# SMS_LITE_SEC_MGR_0_SMS_LITE_SEC_MGR_44234000h register map
Vendor: Texas Instruments
Peripheral module from a debugger description file (folder am62L).
Registers are 32-bit, read-write, reset 0x0 unless marked. A register's access mark holds for its fields unless they carry their own. Offsets are as the file gives them; lines under a group give offsets from that group; [hi:lo] are bit positions; {n}, {i} and the like mark numbered series; 'fields as' and 'values as' point back to an identical list; <NAME> marks a mode.

## SMS_LITE_SEC_MGR
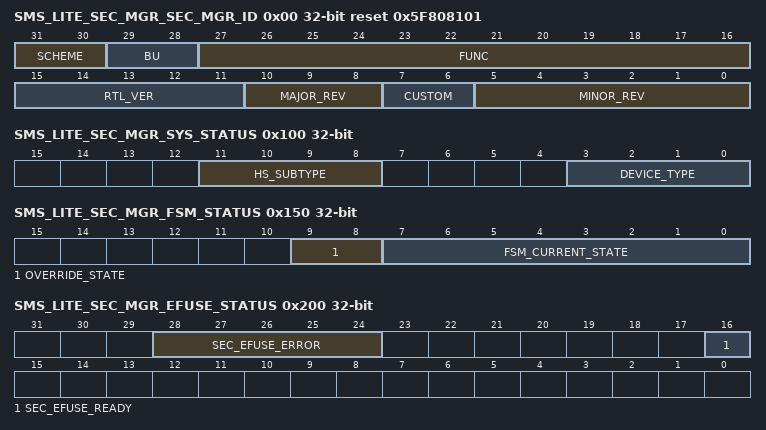
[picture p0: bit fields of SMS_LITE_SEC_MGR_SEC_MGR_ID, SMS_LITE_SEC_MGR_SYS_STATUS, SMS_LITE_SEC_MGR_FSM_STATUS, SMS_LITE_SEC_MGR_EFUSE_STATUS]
0x00 SMS_LITE_SEC_MGR_SEC_MGR_ID ro reset 0x5F808101 — This is the standard TI peripheral ID register that exists at address 0 in the peripheral space
  [31:30] SCHEME — Used to distinguish which ID numbering scheme is used. Reset Source: sms_custom_rst_mod_g_rst_n
  [29:28] BU — BU identifier Reset Source: sms_custom_rst_mod_g_rst_n
  [27:16] FUNC — Module family. Reset Source: sms_custom_rst_mod_g_rst_n
  [15:11] RTL_VER — RTL version. R of X.Y.R.Z Reset Source: sms_custom_rst_mod_g_rst_n
  [10:8] MAJOR_REV — Major revision. X of X.Y.R.Z Reset Source: sms_custom_rst_mod_g_rst_n
  [7:6] CUSTOM — Special version number Reset Source: sms_custom_rst_mod_g_rst_n
  [5:0] MINOR_REV — Minor revision. Y of X.Y.R.Z Reset Source: sms_custom_rst_mod_g_rst_n
0x100 SMS_LITE_SEC_MGR_SYS_STATUS ro — The System Status Register contains status information on the state of the security system. This is the only register that must be read to determine the status of the entire system. It is a readonly register and some bit will be replicated in other registers. This register is reset on POR only.
  [11:8] HS_SUBTYPE — This is the device subtype for HS and EMU devices. 10 Field SecurableElse Security Enforced
  [3:0] DEVICE_TYPE — Decoded device type 4'b00 GENERAL_PURPOSE114'b01 TEST014'b10 EMULATOR014'b10 HIGH_SECURITY10Other BAD
0x150 SMS_LITE_SEC_MGR_FSM_STATUS ro — The FSM Status Register contains Secure FSM state machine information
  [9:8] OVERRIDE_STATE — This is the override status 2'b00 No override2'b01 Override without DMSC2'b10 Reserved2'b11 Override with DMSC
  [7:0] FSM_CURRENT_STATE — This is the state machine FSM current state variable Reset Source: sms_custom_rst_mod_g_rst_n
0x200 SMS_LITE_SEC_MGR_EFUSE_STATUS ro — The EFUSE Status register contains status information on the state of the EFUSE scan chains. It is a read-only register with values from input ports.
  [28:24] SEC_EFUSE_ERROR — These bits reflect the value on the sec_efuse_error port Reset Source: sms_custom_rst_mod_g_rst_n
  [16] SEC_EFUSE_READY — These bits reflect the value on the sec_efuse_ready port Reset Source: sms_custom_rst_mod_g_rst_n
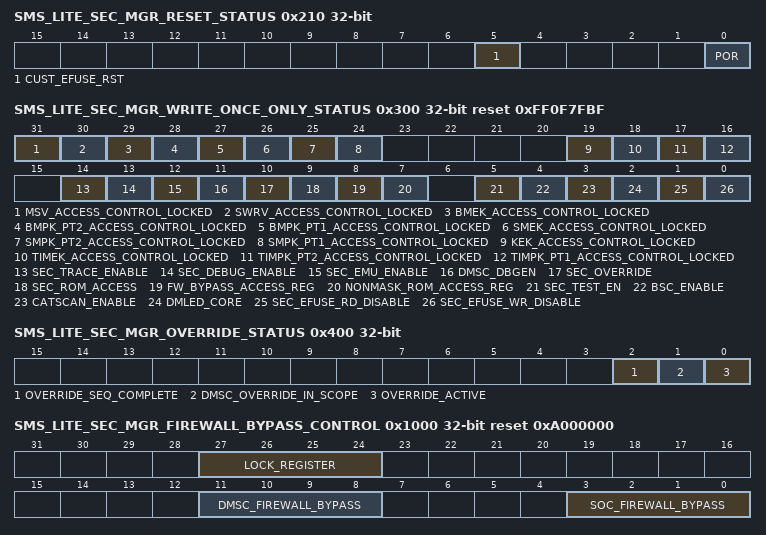
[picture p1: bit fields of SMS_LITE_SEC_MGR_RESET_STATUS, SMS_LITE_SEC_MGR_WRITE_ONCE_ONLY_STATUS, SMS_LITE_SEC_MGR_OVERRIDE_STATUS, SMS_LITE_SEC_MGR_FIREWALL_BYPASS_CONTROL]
0x210 SMS_LITE_SEC_MGR_RESET_STATUS ro — The Reset Status Register provides visibility of resets within the system. These bits are read-only and will be cleared when a 1 is written to a given bit location. They will record the fact that a given reset occurred.
  [5] CUST_EFUSE_RST — Captures reset events on port: sec_efc_fclrz Reset Source: sms_custom_rst_mod_g_rst_n
  [0] POR — Captures reset events on port: por_rst_n Reset Source: sms_custom_rst_mod_g_rst_n
0x300 SMS_LITE_SEC_MGR_WRITE_ONCE_ONLY_STATUS ro reset 0xFF0F7FBF — As a debug aid we need to be able to read the write-once only bits to know their state. This register makes all these write-once only flags visible in current state.
  [31] MSV_ACCESS_CONTROL_LOCKED — 0 MSV access control register locked1 MSV access control register not locked
  [30] SWRV_ACCESS_CONTROL_LOCKED — 0 SWRV access control register locked1 SWRV access control register not locked
  [29] BMEK_ACCESS_CONTROL_LOCKED — 0 BMEK access control register locked1 BMEK access control register not locked
  [28] BMPK_PT2_ACCESS_CONTROL_LOCKED — 0 BMPK-Part2 access control register locked1 BMPK-Part2 access control register not locked
  [27] BMPK_PT1_ACCESS_CONTROL_LOCKED — 0 BMPK-Part1 access control register locked1 BMPK-Part1 access control register not locked
  [26] SMEK_ACCESS_CONTROL_LOCKED — 0 SMEK access control register locked1 SMEK access control register not locked
  [25] SMPK_PT2_ACCESS_CONTROL_LOCKED — 0 SMPK-Part2 access control register locked1 SMPK-Part2 access control register not locked
  [24] SMPK_PT1_ACCESS_CONTROL_LOCKED — 0 SMPK-Part1 access control register locked1 SMPK-Part1 access control register not locked
  [19] KEK_ACCESS_CONTROL_LOCKED — 0 KEK access control register locked1 KEK access control register not locked
  [18] TIMEK_ACCESS_CONTROL_LOCKED — 0 TI MEK access control register locked1 TI MEK access control register not locked
  [17] TIMPK_PT2_ACCESS_CONTROL_LOCKED — 0 TI MPK-Part2 access control register locked1 TI MPK-Part2 access control register not locked
  [16] TIMPK_PT1_ACCESS_CONTROL_LOCKED — 0 TI MPK-Part1 access control register locked1 TI MPK-Part1 access control register not locked
  [14] SEC_TRACE_ENABLE — 0 Secure Trace Enable access control register locked1 Secure Trace Enable access control register not locked
  [13] SEC_DEBUG_ENABLE — 0 Secure Debug Enable access control register locked1 Secure Debug Enable access control register not locked
  [12] SEC_EMU_ENABLE — 0 Secure Emulation Enable access control register locked1 Secure Emulation Enable access control register not locked
  [11] DMSC_DBGEN — 0 DMSC Debug Enable access control register locked1 DMSC Debug Enable access control register not locked
  [10] SEC_OVERRIDE — 0 Security Override access control register locked1 Security Override access control register not locked
  [9] SEC_ROM_ACCESS — 0 Secure ROM access control register locked1 Secure ROM access control register not locked
  [8] FW_BYPASS_ACCESS_REG — 0 Firewall Bypass access control register locked1 Firewall Bypass access control register not locked
  [7] NONMASK_ROM_ACCESS_REG — 0 Non_masked ROM Access control register locked1 Non-Masked ROM Access control register not locked
  [5] SEC_TEST_EN — 0 Secure Test Enable access control register locked1 Secure Test Enable access control register not locked
  [4] BSC_ENABLE — 0 Boundary Scan Enable access control register locked1 Boundary Scan Enable access control register not locked
  [3] CATSCAN_ENABLE — 0 Catscan Enable access control register locked1 Catscan Enable access control register not locked
  [2] DMLED_CORE — 0 DMLED Core control register locked1 DMLED Core control register not locked
  [1] SEC_EFUSE_RD_DISABLE — 0 Security EFUSE Read Disable register locked1 Security EFUSE Read Disable register not locked
  [0] SEC_EFUSE_WR_DISABLE — 0 Security EFUSE Write Disable register locked1 Security EFUSE Write Disable register not locked
0x400 SMS_LITE_SEC_MGR_OVERRIDE_STATUS ro — This Register reflects the status of Override request.
  [2] OVERRIDE_SEQ_COMPLETE — 1 HW Override sequence finished
  [1] DMSC_OVERRIDE_IN_SCOPE — 0 DMSC Override not active1 DMSC Override active
  [0] OVERRIDE_ACTIVE — 0 Override not active0 Override active
0x500 SMS_LITE_SEC_MGR_EFUSE_JTAG_DISABLE_STATUS ro — This Register reflects the status of efuse based JTAG disable feature. Once JTAG has been disabled via Efuse, there can be no debug and TI cannot do any RMA.
  [3:0] JTAG_DISABLE — 4'b00 JTAG not permanently disabled via Efuse00Rest JTAG is disabled
0x700 SMS_LITE_SEC_MGR_TI_MPK_PART1_STATUS_REG_j ro — This register echoes the TI MPK-Part1 value, the MPK value can be muted via MPK Access control register.
  [31:0] TI_MPK — TI MP value as read from TI MPK Data Reg. This register is mere echo of Data Register Reset Source: sms_custom_rst_mod_g_rst_n
0x750 SMS_LITE_SEC_MGR_TI_MPK_PART2_STATUS_REG_j ro — This register echoes the TI MPK-Part2 value, the MPK value can be muted via MPK Access control register.
  fields as SMS_LITE_SEC_MGR_TI_MPK_PART1_STATUS_REG_j
0x780 SMS_LITE_SEC_MGR_TI_MEK_ID_STATUS_REG ro — This register echoes the TI MEK ID value, this is used to ID the key used for MEK.
  [31:0] TI_MEK_ID — TI MEK ID value as read from TI MEK ID data register, this is mere echo of TI MEK ID Register. Reset Source: sms_custom_rst_mod_g_rst_n
0x800 SMS_LITE_SEC_MGR_SMPK_PART1_STATUS_REG_j ro — This register echoes the SMPK-Part1 value, the MPK value can be muted via MPK Access control register.
  [31:0] SMPK — SMPK value as read from SMPK Data Register. This register is mere echo of SMPK Data register. Reset Source: sms_custom_rst_mod_g_rst_n
0x850 SMS_LITE_SEC_MGR_SMPK_PART2_STATUS_REG_j ro — This register echoes the SMPK-Part2 value, the MPK value can be muted via MPK Access control register.
  fields as SMS_LITE_SEC_MGR_SMPK_PART1_STATUS_REG_j
0x880 SMS_LITE_SEC_MGR_SMEK_ID_STATUS_REG ro — This register echoes the SMEK ID value, this is used to ID the key used for SMEK.
  [31:0] SMEK — SMEK ID value as read from SMEK ID data register, this is mere echo of SMEK ID Register. Reset Source: sms_custom_rst_mod_g_rst_n
0x900 SMS_LITE_SEC_MGR_BMPK_PART1_STATUS_REG_j ro — This register echoes the BMPK-Part1 value, the MPK value can be muted via MPK Access control register.
  [31:0] BMPK — BMPK value as read from BMPK Data Register. This register is mere echo of BMPK Data register. Reset Source: sms_custom_rst_mod_g_rst_n
0x950 SMS_LITE_SEC_MGR_BMPK_PART2_STATUS_REG_j ro — This register echoes the BMPK-Part2 value, the MPK value can be muted via MPK Access control register.
  fields as SMS_LITE_SEC_MGR_BMPK_PART1_STATUS_REG_j
0x980 SMS_LITE_SEC_MGR_BMEK_ID_STATUS_REG ro — This register echoes the BMEK ID value, this is used to ID the key used for BMEK.
  [31:0] BMEK — BMEK ID value as read from BMEK ID data register, this is mere echo of BMEK ID Register. Reset Source: sms_custom_rst_mod_g_rst_n
0xD00 SMS_LITE_SEC_MGR_SWRV_STATUS_REG_j ro — This register echoes the SWRV value, the SWRV value can be muted via SWRV Access control register.
  [31:0] SWRV — SWRV value as read from SWRV Data Register. This register is mere echo of SWRV Data register. Reset Source: sms_custom_rst_mod_g_rst_n
0xD50 SMS_LITE_SEC_MGR_MSV_STATUS_REG ro — This register echoes the MSV value, the MSV value can be muted via MSV Access control register.
  [23:0] MSV — MSV value as read from MSV Data Register. This register is mere echo of MSV Data register. Reset Source: sms_custom_rst_mod_g_rst_n
0x1000 SMS_LITE_SEC_MGR_FIREWALL_BYPASS_CONTROL reset 0xA000000 — This register controls the bypass feature for all SoC firewall. Once locked, the register cannot be changed till POR.
  [27:24] LOCK_REGISTER — Unlock code is 0xA, if value is anything else the register locks, once locked this register cannot be changed till POR. Rest Register is locked10 Register is unlocked
  [11:8] DMSC_FIREWALL_BYPASS — Writing code 0xA will put DMSC firewall in bypass mode. Please refer to firewall spec for bypass mode operation. 0 Not in bypass mode10 Bypass
  [3:0] SOC_FIREWALL_BYPASS — Writing code 0xA will put all SoC firewall in bypass mode, excluding DMSC. Please refer to firewall spec for bypass mode operation 0 Not in bypass mode10 Bypass
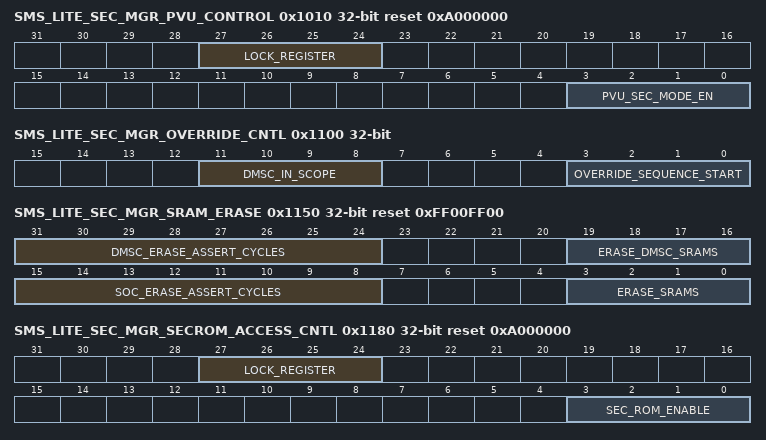
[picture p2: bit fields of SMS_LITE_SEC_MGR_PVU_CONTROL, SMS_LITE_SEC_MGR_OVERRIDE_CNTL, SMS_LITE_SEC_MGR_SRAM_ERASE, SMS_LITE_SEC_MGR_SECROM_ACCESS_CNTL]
0x1010 SMS_LITE_SEC_MGR_PVU_CONTROL reset 0xA000000 — This register controls the security of PVU/IO-MMU module. Once locked, the register cannot be changed till POR.
  [27:24] LOCK_REGISTER — Unlock code is 0xA, if value is anything else the register locks, once locked this register cannot be changed till POR. Reset Source: sms_custom_rst_mod_g_rst_n
  [3:0] PVU_SEC_MODE_EN — Writing code 0xA allows PVC to operate in secure mode. Reset Source: sms_custom_rst_mod_g_rst_n
0x1100 SMS_LITE_SEC_MGR_OVERRIDE_CNTL — Override sequence start register, writing 0xA start the override sequence as documented. This register can only be written once during each POR and the value is sticky.
  [11:8] DMSC_IN_SCOPE — Writing code 0xA will put DMSC also in in scope of override, please refer to flow in previous section. This must be set along with override_sequence_start. Reset Source: sms_custom_rst_mod_g_rst_n
  [3:0] OVERRIDE_SEQUENCE_START — Override sequence start bit, Writing 0xA starts the operation Reset Source: sms_custom_rst_mod_g_rst_n
0x1104 SMS_LITE_SEC_MGR_OVERRIDE_DELAY_LOOP reset 0xFFFF — This register holds delay loop counter to allow DMSC to enter WFI before DMSC override is effeictive.
  [31:0] DMSC_OVERRIDE_DELAY_LOOP_CNT — DMSC Delay loop counter, override is effective when counter reaches Zero. This counter is running on PLL output clock , hence ROM/SW must ensure delay based on system PLL DMSC clock. Reset Source: sms_custom_rst_mod_g_rst_n
0x1150 SMS_LITE_SEC_MGR_SRAM_ERASE reset 0xFF00FF00 — This register control the Erase function of SRAM and ROM access control.
  [31:24] DMSC_ERASE_ASSERT_CYCLES — This MMR control the assertion time of DMSC Erase signal. This is required as certain SRAM erase logic may have time requirement to keep signal asserted. Runs as same clock as Sec-mgr clock. Reset Source: sms_custom_rst_mod_g_rst_n
  [19:16] ERASE_DMSC_SRAMS — Writing code 0xA will send signal to erase DMSC SRAM, this will erase all DMSC SRAM including data and code SRAM. Care must be taken to ensure DMSC Cortex-M3 is in not executing from SRAM when this signal is asserted. Reset Source: sms_custom_rst_mod_g_rst_n
  [15:8] SOC_ERASE_ASSERT_CYCLES — This MMR control the assertion time of SOC Erase signal. This is required as certain SRAM erase logic may have time requirement to keep signal asserted. Runs as same clock as Sec-mgr clock. Reset Source: sms_custom_rst_mod_g_rst_n
  [3:0] ERASE_SRAMS — Writing code 0xA will send signal to all SoC level SRAM to erase the RAM. This bit does not erase DMSC internal SRAM. Reset Source: sms_custom_rst_mod_g_rst_n
0x1180 SMS_LITE_SEC_MGR_SECROM_ACCESS_CNTL reset 0xA000000 — This register controls the Erase function of SRAM and ROM access control.
  [27:24] LOCK_REGISTER — Unlock code is 0xA, if value is anything else the register locks, once locked this register cannot be changed till POR Reset Source: sms_custom_rst_mod_g_rst_n
  [3:0] SEC_ROM_ENABLE — Writing code 0xA will enable access to secure ROM, for all other value the secure ROM is disabled. Reset Source: sms_custom_rst_mod_g_rst_n
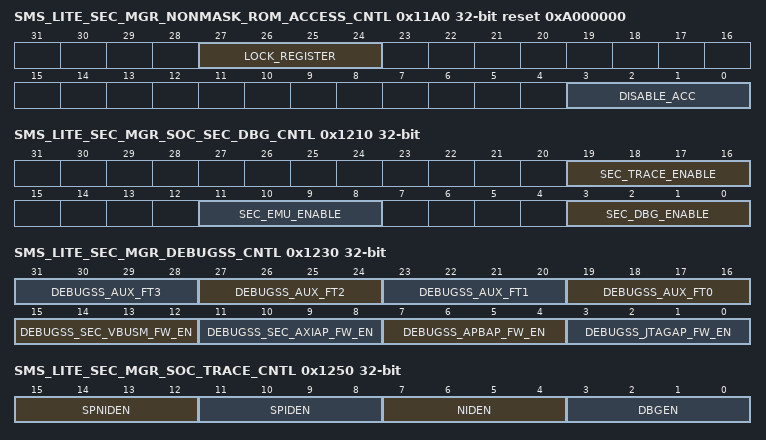
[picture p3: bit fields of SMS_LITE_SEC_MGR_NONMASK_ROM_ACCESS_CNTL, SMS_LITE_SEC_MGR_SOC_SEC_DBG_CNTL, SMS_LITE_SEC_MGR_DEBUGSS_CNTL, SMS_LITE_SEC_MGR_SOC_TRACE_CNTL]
0x11A0 SMS_LITE_SEC_MGR_NONMASK_ROM_ACCESS_CNTL reset 0xA000000 — This register controls the nonmask_rom_enable output of the security manager. This output should be connected to disable access to the non-mask part of the ROM.
  [27:24] LOCK_REGISTER — Unlock code is 0xA, if value is anything else the register locks, once locked this register cannot be changed till POR Reset Source: sms_custom_rst_mod_g_rst_n
  [3:0] DISABLE_ACC — Writing code 0xA will begin the countdown to drive the nonmask_rom_enable output to 0. Reset Source: sms_custom_rst_mod_g_rst_n
0x11A4 SMS_LITE_SEC_MGR_NONMASK_ROM_DISABLE_DELAY_CNTR reset 0x64 — This register contains the Non-Mask ROM Disable Delay counter. This register gets NO initial value from Efuses/Flash. This register defaults to reset state in case of a warm reset.
  [15:0] CNTR — When the Non-Mask ROM disable begins the countdown, this will count down to zero. Reset Source: sms_custom_rst_mod_g_rst_n
0x1200 SMS_LITE_SEC_MGR_DMSC_DEBUG_CNTL — This register controls the DMSC Debug TAP. This register can be locked. This is pure SW managed register with NO initial value from Efuses.
  [3:0] DMSC_DBGEN_ENABLE — Writing code 0xA will enable Debug for DMSC. SW/ROM must be very careful using this. This is set for EMU mode. Reset Source: sms_custom_rst_mod_g_rst_n
0x1210 SMS_LITE_SEC_MGR_SOC_SEC_DBG_CNTL — This register controls the SoC Debug TAPs. This register can be locked. This is pure SW managed register with NO initial value from Efuses.
  [19:16] SEC_TRACE_ENABLE — Writing code 0xA will allow Trace for SoC. This assert Trace signals that are also controlled by “SoC Debug/trace control” register. Once set all security emulation are active. SW/ROM must be very careful using this. Reset Source: sms_custom_rst_mod_g_rst_n
  [11:8] SEC_EMU_ENABLE — Writing code 0xA will allow Secure Emulation for All SoC. Once set all security emulation are active. SW/ROM must be very careful using this. Reset Source: sms_custom_rst_mod_g_rst_n
  [3:0] SEC_DBG_ENABLE — Writing code 0xA will enable full Debug for SoC. This open complete SoC Debug TAPs, except DMSC. Reset Source: sms_custom_rst_mod_g_rst_n
0x1220 SMS_LITE_SEC_MGR_DEBUGSS_DOM reset 0x3CE — This register controls the DebugSS DOM
  [10:0] DEBUGSS_SEC_CTL_DOM — DOM value as per DebugSS spec Reset Source: sms_custom_rst_mod_g_rst_n
0x1230 SMS_LITE_SEC_MGR_DEBUGSS_CNTL — This register controls DebugSS Internal Firewall. This register can be locked. Once locked, the register cannot be changed until POR
  [4n+19:4n+16] DEBUGSS_AUX_FT{n} (n=0..3) — Writing code 0xA will assert signal debugss_aux_ft_signals bit {n} Reset Source: sms_custom_rst_mod_g_rst_n
  [15:12] DEBUGSS_SEC_VBUSM_FW_EN — Writing code 0xA will enable DebugSS internal VBUSM firewall interface, else it is disabled Reset Source: sms_custom_rst_mod_g_rst_n
  [11:8] DEBUGSS_SEC_AXIAP_FW_EN — Writing code 0xA will enable DebugSS internal AXI AP firewall interface, else it is disabled Reset Source: sms_custom_rst_mod_g_rst_n
  [7:4] DEBUGSS_APBAP_FW_EN — Writing code 0xA will enable DebugSS internal APB AP firewall interface, else it is disabled Reset Source: sms_custom_rst_mod_g_rst_n
  [3:0] DEBUGSS_JTAGAP_FW_EN — Writing code 0xA will enable DebugSS internal JTAG firewall interface, else it is disabled Reset Source: sms_custom_rst_mod_g_rst_n
0x1234 SMS_LITE_SEC_MGR_DEBUGSS_DBG_TAP_FW_EN — This register controls the DebugSS Debug Tap. This register can be locked. Once locked, the register cannot be changed till POR. This register gets NO initial value from Efuses
  [31:0] DEBUGSS_DBG_TAP_FW_EN — DebugSS Debug Tap Firewall Enable Reset Source: sms_custom_rst_mod_g_rst_n
0x1238 SMS_LITE_SEC_MGR_DEBUGSS_TEST_TAP_FW_EN — This register controls the DebugSS Test Tap. This register can be locked. Once locked, the register cannot be changed till POR. This register gets NO initial value from Efuses
  [31:0] DEBUGSS_TEST_TAP_FW_EN — DebugSS Test Tap Firewall Enable Reset Source: sms_custom_rst_mod_g_rst_n
0x123C SMS_LITE_SEC_MGR_DEBUGSS_PWR_FW_EN — This register controls the DebugSS Firewall Enable. This register can be locked. Once locked, the register cannot be changed till POR. This register gets NO initial value from Efuses
  [31:0] DEBUGSS_PWR_FW_EN — DebugSS Security Firewall Enable Reset Source: sms_custom_rst_mod_g_rst_n
0x1240 SMS_LITE_SEC_MGR_DEBUGSS_CMX_FW_EN — This register controls the DebugSS Core Enable. This register can be locked. Once locked, the register cannot be changed till POR. This register gets NO initial value from Efuses
  [31:0] DEBUGSS_CMX_FW_EN — DebugSS Core Enable Reset Source: sms_custom_rst_mod_g_rst_n
0x1244 SMS_LITE_SEC_MGR_DEBUGSS_AUX — This register controls the Debugss aux signals. This register can be locked. Once locked, the register cannot be changed till POR. This register gets NO initial value from Efuses.
  [31:0] DEBUGSS_AUX — DebugSS aux reserved signals Reset Source: sms_custom_rst_mod_g_rst_n
0x1250 SMS_LITE_SEC_MGR_SOC_TRACE_CNTL — This register controls SoC Trace. This register can be locked. Once locked, the register cannot be changed till POR. This register gets NO initial value from Efuses.
  [15:12] SPNIDEN — Writing 0xA will enable spniden Reset Source: sms_custom_rst_mod_g_rst_n
  [11:8] SPIDEN — Writing 0xA will enable spiden Reset Source: sms_custom_rst_mod_g_rst_n
  [7:4] NIDEN — Writing 0xA will enable niden Reset Source: sms_custom_rst_mod_g_rst_n
  [3:0] DBGEN — Writing 0xA will enable dbgen Reset Source: sms_custom_rst_mod_g_rst_n
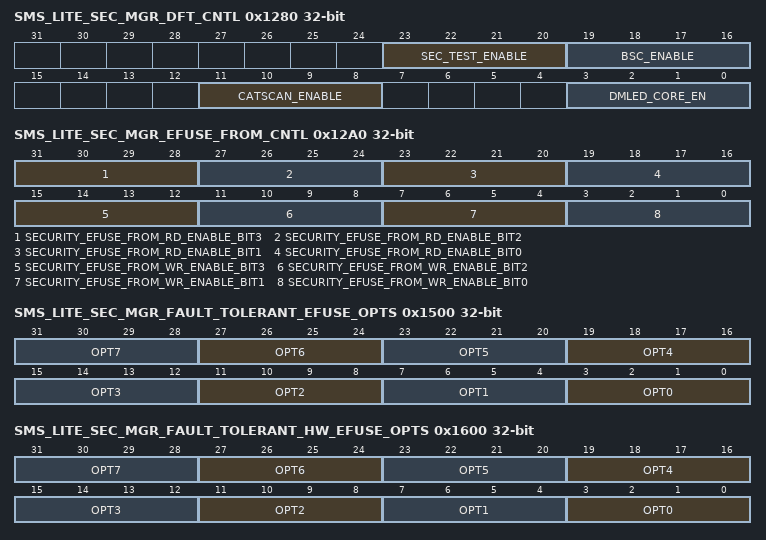
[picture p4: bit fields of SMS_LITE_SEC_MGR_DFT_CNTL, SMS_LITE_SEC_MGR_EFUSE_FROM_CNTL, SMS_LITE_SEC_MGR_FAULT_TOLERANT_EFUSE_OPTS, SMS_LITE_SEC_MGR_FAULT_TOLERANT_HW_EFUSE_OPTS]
0x1280 SMS_LITE_SEC_MGR_DFT_CNTL — This register controls the DFT access of the device. These bits can only be written once during each POR.
  [23:20] SEC_TEST_ENABLE — Control the use of Test Enable. Writing a 0xA will enable test Reset Source: sms_custom_rst_mod_g_rst_n
  [19:16] BSC_ENABLE — Control the use of Boundary Scan Chain. Writing a 0xA will enable BSCAN Reset Source: sms_custom_rst_mod_g_rst_n
  [11:8] CATSCAN_ENABLE — Control the use of the CatScan module. Writing a 0xA will enable CATSCAN Reset Source: sms_custom_rst_mod_g_rst_n
  [3:0] DMLED_CORE_EN — Writing code 0xA will allow DMLED module to operate. Else DMLED mode is disabled. Reset Source: sms_custom_rst_mod_g_rst_n
0x12A0 SMS_LITE_SEC_MGR_EFUSE_FROM_CNTL — This register controls the Efuse access of the device. These bits can only be written once during each POR. This is pure SW managed register with NO initial value from Efuses.
  [31:28] SECURITY_EFUSE_FROM_RD_ENABLE_BIT3 — Reserved Reset Source: sms_custom_rst_mod_g_rst_n
  [27:24] SECURITY_EFUSE_FROM_RD_ENABLE_BIT2 — Customer General OTP Programmable FROM EFUSE Read Disable. 0xA - Reads allowed to Customer General OTP EFUSE FROM. Else - Reads not allowed to Customer General OTP EFUSE FROM. Reset Source: sms_custom_rst_mod_g_rst_n
  [23:20] SECURITY_EFUSE_FROM_RD_ENABLE_BIT1 — Customer Key Material Programmable FROM EFUSE Read Disable. 0xA - Reads allowed to Customer Key Material EFUSE FROM. Else - Reads not allowed to Customer Key Material EFUSE FROM. Reset Source: sms_custom_rst_mod_g_rst_n
  [19:16] SECURITY_EFUSE_FROM_RD_ENABLE_BIT0 — TI Key Material Programmable FROM EFUSE Read Disable. 0xA - Reads allowed to TI Key Material EFUSE FROM. Else - Reads not allowed to TI Key Material EFUSE FROM. Reset Source: sms_custom_rst_mod_g_rst_n
  [15:12] SECURITY_EFUSE_FROM_WR_ENABLE_BIT3 — Reserved Reset Source: sms_custom_rst_mod_g_rst_n
  [11:8] SECURITY_EFUSE_FROM_WR_ENABLE_BIT2 — Customer General OTP Programmable FROM EFUSE Write Disable. 0xA - Writes allowed to Customer General OTP EFUSE FROM. Else - Writes not allowed to Customer General OTP EFUSE FROM. Reset Source: sms_custom_rst_mod_g_rst_n
  [7:4] SECURITY_EFUSE_FROM_WR_ENABLE_BIT1 — Customer Key Material Programmable FROM EFUSE Write Disable. 0xA - Writes allowed to Customer Key Material EFUSE FROM. Else - Writes not allowed to Customer Key Material EFUSE FROM. Reset Source: sms_custom_rst_mod_g_rst_n
  [3:0] SECURITY_EFUSE_FROM_WR_ENABLE_BIT0 — TI Key Material Programmable FROM EFUSE Write Disable. 0xA - Writes allowed to TI Key Material EFUSE FROM. Else - Writes not allowed to TI Key Material EFUSE FROM. Reset Source: sms_custom_rst_mod_g_rst_n
0x1500 SMS_LITE_SEC_MGR_FAULT_TOLERANT_EFUSE_OPTS — This register holds the fault tolerant options that are sensitive from security standpoint. ROM defines these options, ROM can choose to use this option as single bit flag, however for security options fault tolerant field must be used. This register gets initial value from Security Efuse FROM.
  [4n+3:4n] OPT{n} (n=0..7) — If the value is 0xA, then selected option is enabled. Else: Selected option is disabled. ROM code defines this option bit Reset Source: sms_custom_rst_mod_g_rst_n
0x1510 SMS_LITE_SEC_MGR_NON_FAULT_TOLERANT_EFUSE_OPTS — This register holds device config, these are non-fault tolerant. This register gets initial value from Security Efuse FROM.
  [31:0] OPTS — This register holds device config data. ROM code defines these fields Reset Source: sms_custom_rst_mod_g_rst_n
0x1600 SMS_LITE_SEC_MGR_FAULT_TOLERANT_HW_EFUSE_OPTS ro — This register control external signals that can be used to control various/misc security knobs at SoC, it is not defined by security Manager. This register gets initial value from Security Efuse FROM.
  [4n+3:4n] OPT{n} (n=0..7) — If the value is 0xA, then bit[{n}] of ft_hw_efuse_security_ctrl is set (asserted), else it remain clear (de-asserted). ROM/SW cannot change this config, this is true HW config Reset Source: sms_custom_rst_mod_g_rst_n
0x1610 SMS_LITE_SEC_MGR_NON_FAULT_TOLERANT_HW_EFUSE_OPTS ro — This register holds device config, these are non-fault tolerant. This register gets initial value from SecurityEfuse FROM.
  [31:0] OPTS — This register holds device config data. HW uses this to enable/disable security feature. This drives output signal nonft_hw_efuse_security_ctrl[31:0]. ROM/SW cannot change this config, this is true HW config Reset Source: sms_custom_rst_mod_g_rst_n
0x1650 SMS_LITE_SEC_MGR_EXT_SEC_CNTL_SIG — This register holds device config, these are non-fault tolerant. This is pure SW managed register with NO initial value from Efuses.
  [31:0] CNTL — This register holds device config data. SW/ROM can write this value that drives the external pins on IP. This drives nonft_hw_regs_security_ctrl[31:0] Reset Source: sms_custom_rst_mod_g_rst_n
0x1660 SMS_LITE_SEC_MGR_EXT_SEC_DATA_CNTL_j — These set of 4 registers hold the value to be driven on ext_security_data_signal[127:0], security manager takes no action on this data signals. This is pure SW managed register with NO initial value from Efuses.
  [31:0] DATA — These set of 4 registers drive the output signal nonft_hw_regs_security_data[127:0], security manager do not take any action based on value of this signal, it is purely for SoC level security data. Reset Source: sms_custom_rst_mod_g_rst_n
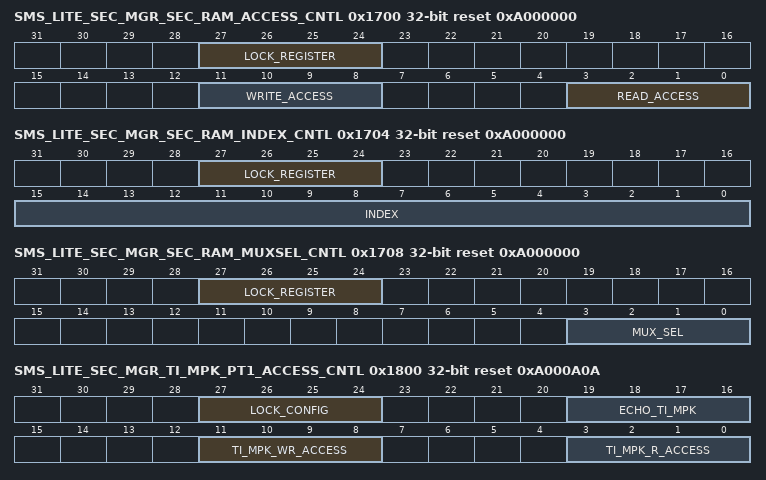
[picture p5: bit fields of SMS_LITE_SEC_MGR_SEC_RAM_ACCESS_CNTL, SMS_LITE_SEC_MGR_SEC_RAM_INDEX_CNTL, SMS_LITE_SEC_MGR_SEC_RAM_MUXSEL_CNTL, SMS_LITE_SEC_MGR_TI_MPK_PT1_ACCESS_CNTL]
0x1700 SMS_LITE_SEC_MGR_SEC_RAM_ACCESS_CNTL reset 0xA000000 — This register controls access to the secure RAM, driving the secure_ram_read_access and secure_ram_write_access pins. Once locked, the register cannot be changed until warm reset or POR. This register gets NO initial value from Efuses. These registers defaults to reset state in case of a warm reset, including unlocking of Lock.
  [27:24] LOCK_REGISTER — Unlock code is 0xA, if value is anything else the register locks, once locked this register cannot be changed until POR or warm reset Reset Source: sms_custom_rst_mod_g_rst_n
  [11:8] WRITE_ACCESS — Writing code 0xA will make the secure RAM writeable Reset Source: sms_custom_rst_mod_g_rst_n
  [3:0] READ_ACCESS — Writing code 0xA will make the secure RAM readable Reset Source: sms_custom_rst_mod_g_rst_n
0x1704 SMS_LITE_SEC_MGR_SEC_RAM_INDEX_CNTL reset 0xA000000 — This register controls the index for the secure RAM, driving the secure_ram_index pins. Once locked, the register cannot be changed until warm reset or POR. This register gets NO initial value from Efuses. This register defaults to reset state in case of a warm reset, including unlocking of Lock.
  [27:24] LOCK_REGISTER — Unlock code is 0xA, if value is anything else the register locks, once locked this register cannot be changed until POR or warm reset Reset Source: sms_custom_rst_mod_g_rst_n
  [15:0] INDEX — This drives the sec_ram_index output to the external secure RAM Reset Source: sms_custom_rst_mod_g_rst_n
0x1708 SMS_LITE_SEC_MGR_SEC_RAM_MUXSEL_CNTL reset 0xA000000 — This register controls the mux selection for the secure RAM, driving the secure_ram_mux_sel pin. Once locked, the register cannot be changed until warm reset or POR. This register gets NO initial value from Efuses. This register defaults to reset state in case of a warm reset, including unlocking of Lock.
  [27:24] LOCK_REGISTER — Unlock code is 0xA, if value is anything else the register locks, once locked this register cannot be changed until POR or warm reset Reset Source: sms_custom_rst_mod_g_rst_n
  [3:0] MUX_SEL — Writing code 0xA will make the sec_ram_mux_sel output go high Reset Source: sms_custom_rst_mod_g_rst_n
0x1800 SMS_LITE_SEC_MGR_TI_MPK_PT1_ACCESS_CNTL reset 0xA000A0A — This Register controls the access/permission of all TI MPK-Part1 Data Registers. If both Read and Write access are not selected, than all TI MPK-Part1 Data registers become invisible both in control and status section. This is pure SW managed register with NO initial value from Efuses.
  [27:24] LOCK_CONFIG — Unlock code is 0xA. If value is anything else the register locks. Once locked this register cannot be changed til POR. Reset Source: sms_custom_rst_mod_g_rst_n
  [19:16] ECHO_TI_MPK — Writing code 0xA will echo TI MPK value in TI MPK read only Status registers. Reset Source: sms_custom_rst_mod_g_rst_n
  [11:8] TI_MPK_WR_ACCESS — 0xA Write Access allowed. Else: No write access Reset Source: sms_custom_rst_mod_g_rst_n
  [3:0] TI_MPK_R_ACCESS — 0xA Read Access allowed. Else: No Read access. Reset Source: sms_custom_rst_mod_g_rst_n
0x1810 SMS_LITE_SEC_MGR_TI_MPK_PT1_DATA_REG_j — This register hold the TI MPK-Part1 value, the TI MPK-Part1 access/permission is controlled TI MPK-Part1 Access control register.
  [31:0] TI_MPK — TI MPK-Part1 value as read from Efuses. Reset Source: sms_custom_rst_mod_g_rst_n
0x1850 SMS_LITE_SEC_MGR_TI_MPK_PT1_BCH — This register holds BCH value for TI MPK-Part1. This register gets initial value from Security Efuse FROM
  [31:0] BCH — TI MPK-Part1 BCH Register. Initial value is loaded by HW, ROM reads Raw TI MPK-Part1 data and BCH register to carry out error correction. If the BCH register is Zero, then ROM must ignore BCH check and treat the raw data as golden. Reset Source: sms_custom_rst_mod_g_rst_n
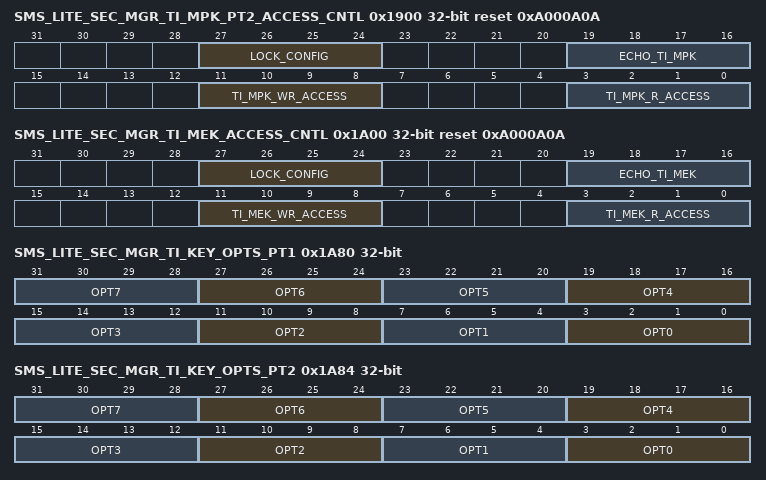
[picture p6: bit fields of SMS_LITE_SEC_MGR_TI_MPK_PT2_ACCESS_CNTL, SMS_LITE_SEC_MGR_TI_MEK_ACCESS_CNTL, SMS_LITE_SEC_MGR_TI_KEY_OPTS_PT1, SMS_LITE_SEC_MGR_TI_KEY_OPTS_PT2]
0x1900 SMS_LITE_SEC_MGR_TI_MPK_PT2_ACCESS_CNTL reset 0xA000A0A — This Register controls the access/permission of all TI MPK-Part2 Data Registers. If both Read and Write access are not selected, than all TI MPK-Part2 Data registers become invisible both in control and status section. This is pure SW managed register with NO initial value from Efuses.
  fields as SMS_LITE_SEC_MGR_TI_MPK_PT1_ACCESS_CNTL
0x1910 SMS_LITE_SEC_MGR_TI_MPK_PT2_DATA_REG_j — This register hold the TI MPK-Part2 value, the TI MPK-Part2 access/permission is controlled TI MPK-Part2 Access control register.
  [31:0] TI_MPK — TI MPK-Part2 value as read from Efuses. Reset Source: sms_custom_rst_mod_g_rst_n
0x1950 SMS_LITE_SEC_MGR_TI_MPK_PT2_BCH — This register holds BCH value for TI MPK-Part2. This register gets initial value from Security Efuse FROM
  [31:0] BCH — TI MPK-Part2 BCH Register. Initial value is loaded by HW, ROM reads Raw TI MPK-Part2 data and BCH register to carry out error correction. If the BCH register is Zero, then ROM must ignore BCH check and treat the raw data as golden. Reset Source: sms_custom_rst_mod_g_rst_n
0x1A00 SMS_LITE_SEC_MGR_TI_MEK_ACCESS_CNTL reset 0xA000A0A — This Register controls the access/permission of all TI MEK Data Registers. If both Read and Write access are not selected, than all TI MEK Data registers become invisible.
  [27:24] LOCK_CONFIG — Unlock code is 0xA. If value is anything else the register locks, once locked this register cannot be changed til POR Reset Source: sms_custom_rst_mod_g_rst_n
  [19:16] ECHO_TI_MEK — Writing code 0xA will echo TI MEK ID value in status register, this can used by public code to check the key used for Encryption. This must NOT be function of actual TI MEK value, rather a mere index. Reset Source: sms_custom_rst_mod_g_rst_n
  [11:8] TI_MEK_WR_ACCESS — 0xA Write Access allowed. Else: No write access Reset Source: sms_custom_rst_mod_g_rst_n
  [3:0] TI_MEK_R_ACCESS — 0xA Read Access allowed. Else: No Read access. Reset Source: sms_custom_rst_mod_g_rst_n
0x1A04 SMS_LITE_SEC_MGR_TI_MEK_ID — TI MEK ID Data Register
  [31:0] TI_MEK_ID — TI MEK ID, used by public code to check the key used for Encryption. This must NOT be function of actual TI MEK value, rather a mere index. SW has full flexibility to use these 32-bits as desired to ID the TI MEK key. Reset Source: sms_custom_rst_mod_g_rst_n
0x1A10 SMS_LITE_SEC_MGR_TI_MEK_DATA_REG_j — This register hold the TI MEK value, the TI MEK access/permission is controlled MEK Access control register.
  [31:0] TI_MEK — TI MEK value as read from Efuses. Reset Source: sms_custom_rst_mod_g_rst_n
0x1A50 SMS_LITE_SEC_MGR_TI_MEK_BCH — This register holds BCH value for TI MEK. This register gets initial value from Security Efuse FROM
  [31:0] BCH — TI MEK BCH Register. Initial value is loaded by HW, ROM reads Raw TI MEK data and BCH register to carry out error correction. If the BCH register is Zero, then ROM must ignore BCH check and treat the data as golden. Reset Source: sms_custom_rst_mod_g_rst_n
0x1A80 SMS_LITE_SEC_MGR_TI_KEY_OPTS_PT1 — This field is TI defined Keys options
  [4n+3:4n] OPT{n} (n=0..7) — If the value is 0xA, option is active. Else option is de-activated Reset Source: sms_custom_rst_mod_g_rst_n
0x1A84 SMS_LITE_SEC_MGR_TI_KEY_OPTS_PT2 — This field is TI defined Keys options
  fields as SMS_LITE_SEC_MGR_TI_KEY_OPTS_PT1
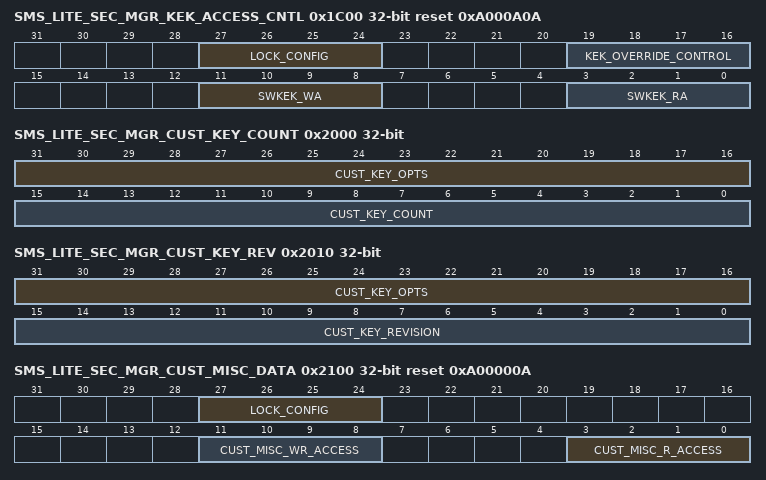
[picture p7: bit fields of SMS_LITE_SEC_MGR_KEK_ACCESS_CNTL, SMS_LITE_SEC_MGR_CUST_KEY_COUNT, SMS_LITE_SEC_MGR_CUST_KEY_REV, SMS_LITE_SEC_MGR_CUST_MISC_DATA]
0x1C00 SMS_LITE_SEC_MGR_KEK_ACCESS_CNTL reset 0xA000A0A — This Register controls the access/permission of all KEK Data Registers. If both Read and Write access are not selected, than all KEK Data registers become invisible.
  [27:24] LOCK_CONFIG — Unlock code is 0xA, if value is anything else the register locks, once locked this register cannot be changed til POR Reset Source: sms_custom_rst_mod_g_rst_n
  [19:16] KEK_OVERRIDE_CONTROL — 0xA Override KEK output to value from KEK override registers. Else KEK is as coming from KEK Efuses Reset Source: sms_custom_rst_mod_g_rst_n
  [11:8] SWKEK_WA — 0xA Write Access allowed to SW KEK register. Else No write access Reset Source: sms_custom_rst_mod_g_rst_n
  [3:0] SWKEK_RA — 0xA Write Access allowed to SW KEK register. Else No write access Reset Source: sms_custom_rst_mod_g_rst_n
0x1C10 SMS_LITE_SEC_MGR_SW_KEK_DATA_REG_j — These 8 registers register hold the KEK override value. This is pure SW managed register with NO initial value from Efuses
  [31:0] SW_KEK — SW defined KEK override value. Reset Source: sms_custom_rst_mod_g_rst_n
0x2000 SMS_LITE_SEC_MGR_CUST_KEY_COUNT ro — This register hold the number Keys that has been provisioned, this register must be written upfront during customer initial keys provisioning. This register must not be written in field else there can be security breach. This register gets initial value from Security Efuse FROM
  [31:16] CUST_KEY_OPTS — Customer defined efuse bits. Reset Source: sms_custom_rst_mod_g_rst_n
  [15:0] CUST_KEY_COUNT — 16-bit for field, double redundancy, that is used to keep count of keys provisioned in device. 0 - No customer keys present the system will boot from TI keys. Customer key Count must be non-zero for HS/EMU device to transaction from HS-FS/EMU-FS (Field Securable) to HS-SE/EMU-SE (Security Enforced) Reset Source: sms_custom_rst_mod_g_rst_n
0x2010 SMS_LITE_SEC_MGR_CUST_KEY_REV ro — This register holds what key (TI Key, SMPK and BMPK) is active at this point. This register gets initial value from Security Efuse FROM.
  [31:16] CUST_KEY_OPTS — Customer defined efuse bits. Reset Source: sms_custom_rst_mod_g_rst_n
  [15:0] CUST_KEY_REVISION — 16-bit for field , double redundancy. 0 - Use TI keys as root-of-trust. Else use Customer keys (SMPK/BMPK). Customer key Revision must be non-zero for HS/EMU device to transaction from HS-FS/EMU-FS (Field Securable) to HS-SE/EMU-SE (Security Enforced) Reset Source: sms_custom_rst_mod_g_rst_n
0x2100 SMS_LITE_SEC_MGR_CUST_MISC_DATA reset 0xA00000A — This Register controls the access/permission of all Customer Misc Data Registers. If both Read and Write access are not selected, than all CUST MISC Data registers become invisible.
  [27:24] LOCK_CONFIG — Unlock code is 0xA, if value is anything else the register locks, once locked this register cannot be changed till POR. Reset Source: sms_custom_rst_mod_g_rst_n
  [11:8] CUST_MISC_WR_ACCESS — 0xA Write Access allowed. Else: No write access Reset Source: sms_custom_rst_mod_g_rst_n
  [3:0] CUST_MISC_R_ACCESS — 0xA Read Access allowed. Else: No Read access. Reset Source: sms_custom_rst_mod_g_rst_n
0x2110 SMS_LITE_SEC_MGR_CUST_MISC_DATA_REG_j — This register hold the CUST MISC value, the CUST MISC access/permission is controlled CUST MISC Access control register. This can be used by customer to store critical security flags/data.
  [31:0] CUST_MISC — CUST MISC value. ROM/HW does no action based on value of this register. Reset Source: sms_custom_rst_mod_g_rst_n
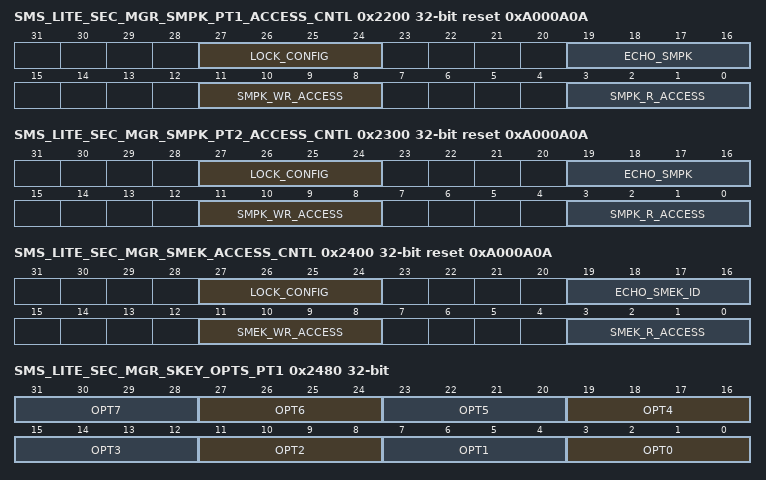
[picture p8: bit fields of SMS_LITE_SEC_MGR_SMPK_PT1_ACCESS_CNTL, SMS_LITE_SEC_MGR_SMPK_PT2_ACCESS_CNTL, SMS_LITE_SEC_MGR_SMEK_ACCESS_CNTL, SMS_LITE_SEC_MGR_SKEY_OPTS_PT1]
0x2200 SMS_LITE_SEC_MGR_SMPK_PT1_ACCESS_CNTL reset 0xA000A0A — This Register controls the access/permission of all SMPK-Part1 Data Registers. If both Read and Write access are not selected, than all SMPK Data registers become invisible.
  [27:24] LOCK_CONFIG — Unlock code is 0xA, if value is anything else the register locks, once locked this register cannot be changed till POR. Reset Source: sms_custom_rst_mod_g_rst_n
  [19:16] ECHO_SMPK — Writing code 0xA will echo SMPK value in SMPK read only Status registers. Reset Source: sms_custom_rst_mod_g_rst_n
  [11:8] SMPK_WR_ACCESS — 0xA Write Access allowed. Else: No write access Reset Source: sms_custom_rst_mod_g_rst_n
  [3:0] SMPK_R_ACCESS — 0xA Read Access allowed. Else: No Read access. Reset Source: sms_custom_rst_mod_g_rst_n
0x2210 SMS_LITE_SEC_MGR_SMPK_PT1_DATA_REG_j — This register hold the SMPK-Part1 value, the SMPK-Part1 access/permission is controlled SMPK-Part1 Access control register.
  [31:0] SMPK — SMPK-Part1 value as read from Efuses Reset Source: sms_custom_rst_mod_g_rst_n
0x2250 SMS_LITE_SEC_MGR_SMPK_PT1_BCH — This register holds BCH value for SMPK-Part1. This register gets initial value from Security Efuse FROM
  [31:0] BCH — SMPK-Part1 BCH Register. Initial value is loaded by HW, ROM reads Raw SMPK-Part1 data and BCH register to carry out error correction. If the BCH register is Zero, then ROM must ignore BCH check and treat the data as golden Reset Source: sms_custom_rst_mod_g_rst_n
0x2300 SMS_LITE_SEC_MGR_SMPK_PT2_ACCESS_CNTL reset 0xA000A0A — This Register controls the access/permission of all SMPK-Part2 Data Registers. If both Read and Write access are not selected, than all SMPK-Part2 Data registers become invisible in both control and status sections.
  fields as SMS_LITE_SEC_MGR_SMPK_PT1_ACCESS_CNTL
0x2310 SMS_LITE_SEC_MGR_SMPK_PT2_DATA_REG_j — This register hold the SMPK-Part2 value, the SMPK-Part2 access/permission is controlled SMPK-Part2 Access control register.
  [31:0] SMPK — SMPK-Part2 value as read from Efuses Reset Source: sms_custom_rst_mod_g_rst_n
0x2350 SMS_LITE_SEC_MGR_SMPK_PT2_BCH — This register holds BCH value for SMPK-Part2. This register gets initial value from Security Efuse FROM
  [31:0] BCH — SMPK-Part2 BCH Register. Initial value is loaded by HW, ROM reads Raw SMPK-Part2 data and BCH register to carry out error correction. If the BCH register is Zero, then ROM must ignore BCH check and treat the data as golden Reset Source: sms_custom_rst_mod_g_rst_n
0x2400 SMS_LITE_SEC_MGR_SMEK_ACCESS_CNTL reset 0xA000A0A — This Register controls the access/permission of all SMEK Data Registers. If both Read and Write access are not selected, than all SMEK Data registers become invisible.
  [27:24] LOCK_CONFIG — Writing code 0xA lock the config, once locked TI MPK access as set in this register cannot be changed till POR. Reset Source: sms_custom_rst_mod_g_rst_n
  [19:16] ECHO_SMEK_ID — Writing code 0xA will echo SMEK ID value in status register, this can used by public code to check the key used for Encryption. This must NOT be function of actual SMEK value, rather a mere index. Reset Source: sms_custom_rst_mod_g_rst_n
  [11:8] SMEK_WR_ACCESS — 0xA Write Access allowed. Else: No write access Reset Source: sms_custom_rst_mod_g_rst_n
  [3:0] SMEK_R_ACCESS — 0xA Read Access allowed. Else: No Read access. Reset Source: sms_custom_rst_mod_g_rst_n
0x2404 SMS_LITE_SEC_MGR_SMEK_ID — SMEK ID Data Register
  [31:0] SMEK_ID — SMEK ID, used by public code to check the key used for Encryption. This must NOT be function of actual SMEK value, rather a mere index. SW has full flexibility to use these 32-bits as desired to ID the SMEK key. Reset Source: sms_custom_rst_mod_g_rst_n
0x2410 SMS_LITE_SEC_MGR_SMEK_DATA_REG_j — This register hold the SMEK value, the SMEK access/permission is controlled MEK Access control register.
  [31:0] SMEK — SMEK value as read from Efuses Reset Source: sms_custom_rst_mod_g_rst_n
0x2450 SMS_LITE_SEC_MGR_SMEK_BCH — This register holds BCH value for SMEK-BCH. This register gets initial value from Security Efuse FROM
  [31:0] BCH — SMEK BCH Register. Initial value is loaded by HW, ROM reads Raw SMEK data and BCH register to carry out error correction. If the BCH register is Zero, then ROM must ignore BCH check and treat the data as golden Reset Source: sms_custom_rst_mod_g_rst_n
0x2480 SMS_LITE_SEC_MGR_SKEY_OPTS_PT1 — This field is Customer defined Keys options. This register is populated by ROM code, with NO initial from Efuses.
  [4n+3:4n] OPT{n} (n=0..7) — If the value is 0xA, option is active. Else, option is deactivated Reset Source: sms_custom_rst_mod_g_rst_n
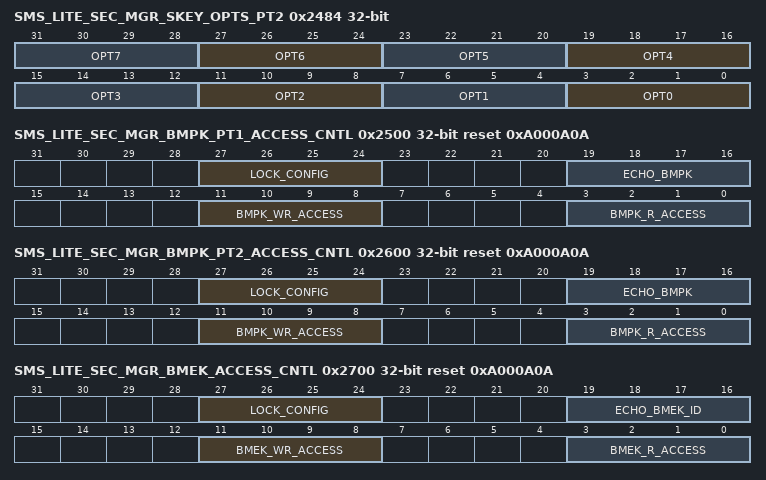
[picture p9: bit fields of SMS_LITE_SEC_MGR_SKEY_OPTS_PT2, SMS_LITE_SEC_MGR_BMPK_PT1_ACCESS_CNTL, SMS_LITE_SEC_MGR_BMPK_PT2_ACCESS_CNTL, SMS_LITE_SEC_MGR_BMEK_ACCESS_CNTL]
0x2484 SMS_LITE_SEC_MGR_SKEY_OPTS_PT2 — This field is Customer defined Keys options. This register is populated by ROM code, with NO initial from Efuses.
  fields as SMS_LITE_SEC_MGR_SKEY_OPTS_PT1
0x2500 SMS_LITE_SEC_MGR_BMPK_PT1_ACCESS_CNTL reset 0xA000A0A — This Register controls the access/permission of all BMPK-Part1 Data Registers. If both Read and Write access are not selected, than all BMPK-Part1 Data registers become invisible in both status and control sections.
  [27:24] LOCK_CONFIG — Unlock code is 0xA, if value is anything else the register locks, once locked this register cannot be changed till POR. Reset Source: sms_custom_rst_mod_g_rst_n
  [19:16] ECHO_BMPK — Writing code 0xA will echo BMPK value in BMPK read only Status registers Reset Source: sms_custom_rst_mod_g_rst_n
  [11:8] BMPK_WR_ACCESS — 0xA Write Access allowed. Else: No write access. Reset Source: sms_custom_rst_mod_g_rst_n
  [3:0] BMPK_R_ACCESS — 0xA Read Access allowed. Else: No Read access. Reset Source: sms_custom_rst_mod_g_rst_n
0x2510 SMS_LITE_SEC_MGR_BMPK_PT1_DATA_REG_j — This register hold the BMPK-Part1 value, the BMPK-Part1 access/permission is controlled BMPK-Part1 Access control register.
  [31:0] BMPK — BMPK-Part1 value as read from Efuses Reset Source: sms_custom_rst_mod_g_rst_n
0x2550 SMS_LITE_SEC_MGR_BMPK_PT1_BCH — This register holds BCH value for BMPK-Part1. This register gets initial value from Security Efuse FROM
  [31:0] BCH — BMPK-Part1 BCH Register. Initial value is loaded by HW, ROM reads Raw BMPK-Part1 data and BCH register to carry out error correction. If the BCH register is Zero, then ROM must ignore BCH check and treat the data as golden Reset Source: sms_custom_rst_mod_g_rst_n
0x2600 SMS_LITE_SEC_MGR_BMPK_PT2_ACCESS_CNTL reset 0xA000A0A — This Register controls the access/permission of all BMPK-Part2 Data Registers. If both Read and Write access are not selected, than all BMPK-Part2 Data registers become invisible in both status and control sections.
  fields as SMS_LITE_SEC_MGR_BMPK_PT1_ACCESS_CNTL
0x2610 SMS_LITE_SEC_MGR_BMPK_PT2_DATA_REG_j — This register hold the BMPK-Part2 value, the BMPK-Part2 access/permission is controlled BMPK-Part2 Access control register.
  [31:0] BMPK — BMPK-Part2 value as read from Efuses Reset Source: sms_custom_rst_mod_g_rst_n
0x2650 SMS_LITE_SEC_MGR_BMPK_PT2_BCH — This register holds BCH value for BMPK-Part2. This register gets initial value from Security Efuse FROM
  [31:0] BCH — BMPK-Part2 BCH Register. Initial value is loaded by HW, ROM reads Raw BMPK-Part2 data and BCH register to carry out error correction. If the BCH register is Zero, then ROM must ignore BCH check and treat the data as golden Reset Source: sms_custom_rst_mod_g_rst_n
0x2700 SMS_LITE_SEC_MGR_BMEK_ACCESS_CNTL reset 0xA000A0A — This Register controls the access/permission of all BMEK Data Registers. If both Read and Write access are not selected, than all BMEK Data registers become invisible.
  [27:24] LOCK_CONFIG — Unlock code is 0xA, if value is anything else the register locks, once locked this register cannot be changed till POR. Reset Source: sms_custom_rst_mod_g_rst_n
  [19:16] ECHO_BMEK_ID — Writing code 0xA will echo BMEK ID value in status register, this can used by public code to check the key used for Encryption. This must NOT be function of actual BMEK value, rather a mere index. Reset Source: sms_custom_rst_mod_g_rst_n
  [11:8] BMEK_WR_ACCESS — 0xA Write Access allowed. Else: No write access Reset Source: sms_custom_rst_mod_g_rst_n
  [3:0] BMEK_R_ACCESS — 0xA Read Access allowed. Else: No Read access. Reset Source: sms_custom_rst_mod_g_rst_n
0x2704 SMS_LITE_SEC_MGR_BMEK_ID — BMEK ID Data Register
  [31:0] BMEK_ID — BMEK ID, used by public code to check the key used for Encryption. This must NOT be function of actual BMEK value, rather a mere index. SW has full flexibility to use these 32-bits as desired to ID the BMEK key. Reset Source: sms_custom_rst_mod_g_rst_n
0x2710 SMS_LITE_SEC_MGR_BMEK_DATA_REG_j — This register hold the BMEK value, the BMEK access/permission is controlled MEK Access control register.
  [31:0] BMEK — BMEK value as read from Efuses Reset Source: sms_custom_rst_mod_g_rst_n
0x2750 SMS_LITE_SEC_MGR_BMEK_BCH — This register holds BCH value for BMEK-BCH. This register gets initial value from Security Efuse FROM
  [31:0] BCH — BMEK BCH Register. Initial value is loaded by HW, ROM reads Raw BMEK data and BCH register to carry out error correction. If the BCH register is Zero, then ROM must ignore BCH check and treat the raw data asgolden Reset Source: sms_custom_rst_mod_g_rst_n
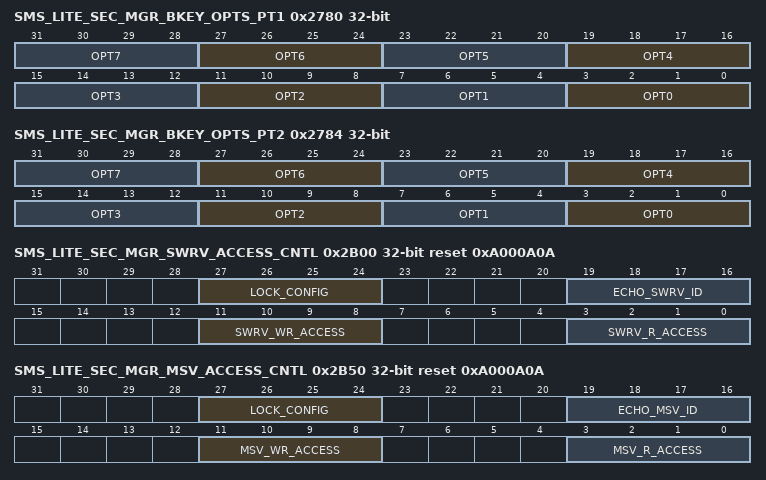
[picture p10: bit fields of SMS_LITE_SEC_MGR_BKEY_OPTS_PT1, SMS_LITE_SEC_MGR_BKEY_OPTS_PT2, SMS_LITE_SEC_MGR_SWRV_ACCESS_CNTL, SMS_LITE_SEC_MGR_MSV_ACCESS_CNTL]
0x2780 SMS_LITE_SEC_MGR_BKEY_OPTS_PT1 — This field is Customer defined Keys options. This register is populated by ROM code, with NO initial from Efuses.
  fields as SMS_LITE_SEC_MGR_SKEY_OPTS_PT1
0x2784 SMS_LITE_SEC_MGR_BKEY_OPTS_PT2 — This field is Customer defined Keys options. This register is populated by ROM code, with NO initial from Efuses.
  fields as SMS_LITE_SEC_MGR_SKEY_OPTS_PT1
0x2B00 SMS_LITE_SEC_MGR_SWRV_ACCESS_CNTL reset 0xA000A0A — This Register controls the access/permission of all SWRV Data Registers. If both Read and Write access are not selected, than all SWRV Data registers become invisible.
  [27:24] LOCK_CONFIG — Unlock code is 0xA, if value is anything else the register locks, once locked this register cannot be changed till POR Reset Source: sms_custom_rst_mod_g_rst_n
  [19:16] ECHO_SWRV_ID — Writing code 0xA will echo SWRV ID value in status register, this can used by public code to check the key used for Encryption. This must NOT be function of actual SWRV value, rather a mere index. Reset Source: sms_custom_rst_mod_g_rst_n
  [11:8] SWRV_WR_ACCESS — 0xA Write Access allowed. Else: No write access Reset Source: sms_custom_rst_mod_g_rst_n
  [3:0] SWRV_R_ACCESS — 0xA Read Access allowed. Else: No Read access. Reset Source: sms_custom_rst_mod_g_rst_n
0x2B10 SMS_LITE_SEC_MGR_SWRV_DATA_REG_j — This register hold the SWRV value, the SWRV access/permission is controlled SWRV Access control register.
  [31:0] SWRV — SWRV value as read from efuse. ROM/SW does triple redundancy on these bits. Reset Source: sms_custom_rst_mod_g_rst_n
0x2B50 SMS_LITE_SEC_MGR_MSV_ACCESS_CNTL reset 0xA000A0A — This Register controls the access/permission of all MSV Data Registers. If both Read and Write access are not selected, than all MSV Data registers become invisible. This is pure SW managed register with NO initial value from Efuses
  [27:24] LOCK_CONFIG — Unlock code is 0xA, if value is anything else the register locks, once locked this register cannot be changed till POR Reset Source: sms_custom_rst_mod_g_rst_n
  [19:16] ECHO_MSV_ID — Writing code 0xA will echo MSV ID value in status register, this can used by public code to check the key used for Encryption. This must NOT be function of actual MSV value, rather a mere index. Reset Source: sms_custom_rst_mod_g_rst_n
  [11:8] MSV_WR_ACCESS — 0xA Write Access allowed. Else: No write access Reset Source: sms_custom_rst_mod_g_rst_n
  [3:0] MSV_R_ACCESS — 0xA Read Access allowed. Else: No Read access. Reset Source: sms_custom_rst_mod_g_rst_n
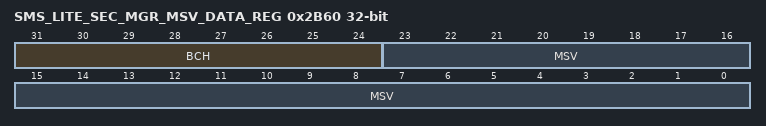
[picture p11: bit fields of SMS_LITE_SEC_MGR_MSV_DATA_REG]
0x2B60 SMS_LITE_SEC_MGR_MSV_DATA_REG — This registers hold the MSV value, the MSV access/permission is controlled MSV Access control register. This register gets initial value from Security Efuse FROM
  [31:24] BCH — BCH value of MSV register[23:0]. If the BCH register is Zero, then ROM must ignore BCH check and treat the raw data as golden Reset Source: sms_custom_rst_mod_g_rst_n
  [23:0] MSV — MSV value. ROM/SW does BCH Reset Source: sms_custom_rst_mod_g_rst_n
0x3000 SMS_LITE_SEC_MGR_OTP_VAL_REG_j ro — General purpose OTP is array of efuses that is defined by customer, ROM or HW takes no action based on values of these OTP, customer can use these OTP to create customer specific data. The amount of OTP bits are defined at time of RTL generation via parameter. Security manager supports min 128 bits to - max 1Kbits. As part of PORz, Security Manager scans the customer OTP and loads vlaues into Registers for ease of SW use. Security Manager does not provide any feature to write data to Efuses based on register value. Firewall at DMSC level provides protection for OTP MMR space
  [31:0] OTP_DATA — OTP data as read from Efuses Reset Source: sms_custom_rst_mod_g_rst_n
